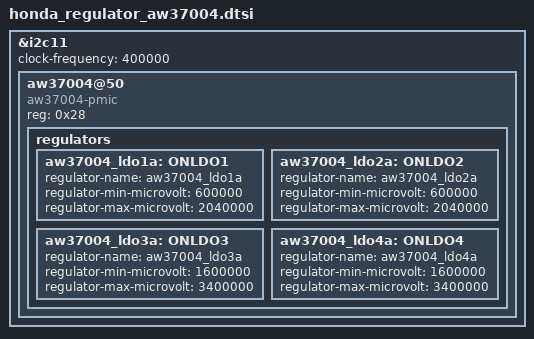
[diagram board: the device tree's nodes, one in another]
/* SPDX-License-Identifier: GPL-2.0
 *
 * Copyright (C) 2021 MediaTek Inc.
 */

/* aw37004 */
/*
&pio {
	aw37004_default: state_default_a {
		pins_cmd_dat {
			pinmux = <PINMUX_GPIO1__FUNC_GPIO1>;
		};
	};
	// GPIO01 pull up to enable aw37004 supply
	aw37004_reset_high: state_reset_high_a {
		pins_cmd_dat {
			pinmux = <PINMUX_GPIO1__FUNC_GPIO1>;
			slew-rate = <1>;
			output-high;
		};
	};
	aw37004_reset_low: state_reset_low_a {
		pins_cmd_dat {
			pinmux = <PINMUX_GPIO1__FUNC_GPIO1>;
			slew-rate = <1>;
			output-low;
		};
	};
};
*/
&i2c11 {
	clock-frequency = <400000>;
	aw37004@50 {
		compatible = "aw37004-pmic";
		reg = <0x28>;
		/*
		pinctrl-names = "default", "reset_high", "reset_low";
		pinctrl-0 = <&aw37004_default>;
		pinctrl-1 = <&aw37004_reset_high>;
		pinctrl-2 = <&aw37004_reset_low>;
		*/
		regulators {
			//dvdd1
			aw37004_ldo1a:ONLDO1 {
				regulator-name = "aw37004_ldo1a";
				regulator-min-microvolt = <600000>;
				regulator-max-microvolt = <2040000>;
			};
			//dvdd2
			aw37004_ldo2a:ONLDO2 {
				regulator-name = "aw37004_ldo2a";
				regulator-min-microvolt = <600000>;
				regulator-max-microvolt = <2040000>;
			};
			//avdd1
			aw37004_ldo3a:ONLDO3 {
				regulator-name = "aw37004_ldo3a";
				regulator-min-microvolt = <1600000>;
				regulator-max-microvolt = <3400000>;
			};
			//avdd2
			aw37004_ldo4a:ONLDO4 {
				regulator-name = "aw37004_ldo4a";
				regulator-min-microvolt = <1600000>;
				regulator-max-microvolt = <3400000>;
			};
		};
	};
};
